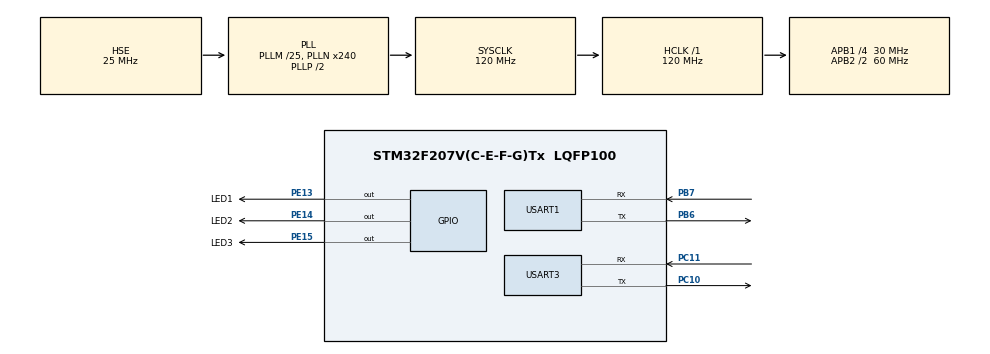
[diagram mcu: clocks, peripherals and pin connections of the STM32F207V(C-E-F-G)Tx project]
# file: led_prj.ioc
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Mcu.Family=STM32F2
Mcu.Name=STM32F207V(C-E-F-G)Tx
Mcu.Package=LQFP100
NVIC.PriorityGroup=NVIC_PRIORITYGROUP_4
PB6.Mode=Asynchronous
PB6.Signal=USART1_TX
PB7.Mode=Asynchronous
PB7.Signal=USART1_RX
PC10.Mode=Asynchronous
PC10.Signal=USART3_TX
PC11.Mode=Asynchronous
PC11.Signal=USART3_RX
PE13.GPIO_Label=LED1
PE13.PinState=GPIO_PIN_SET
PE13.Signal=GPIO_Output
PE14.GPIO_Label=LED2
PE14.PinState=GPIO_PIN_SET
PE14.Signal=GPIO_Output
PE15.GPIO_Label=LED3
PE15.PinState=GPIO_PIN_SET
PE15.Signal=GPIO_Output
PH0-OSC_IN.Mode=HSE-External-Oscillator
PH0-OSC_IN.Signal=RCC_OSC_IN
PH1-OSC_OUT.Mode=HSE-External-Oscillator
PH1-OSC_OUT.Signal=RCC_OSC_OUT
ProjectManager.HeapSize=0x200
ProjectManager.StackSize=0x400
ProjectManager.TargetToolchain=STM32CubeIDE
RCC.48MHZClocksFreq_Value=60000000
RCC.AHBFreq_Value=120000000
RCC.APB1CLKDivider=RCC_HCLK_DIV4
RCC.APB1Freq_Value=30000000
RCC.APB1TimFreq_Value=60000000
RCC.APB2CLKDivider=RCC_HCLK_DIV2
RCC.APB2Freq_Value=60000000
RCC.APB2TimFreq_Value=120000000
RCC.CortexFreq_Value=120000000
RCC.HCLKFreq_Value=120000000
RCC.HSE_VALUE=25000000
RCC.HSI_VALUE=16000000
RCC.LSE_VALUE=32768
RCC.PLLM=25
RCC.PLLN=240
RCC.PLLSourceVirtual=RCC_PLLSOURCE_HSE
RCC.SYSCLKFreq_VALUE=120000000
RCC.SYSCLKSource=RCC_SYSCLKSOURCE_PLLCLK
RCC.VCOOutputFreq_Value=240000000
USART1.VirtualMode=VM_ASYNC
USART3.VirtualMode=VM_ASYNC
board=custom

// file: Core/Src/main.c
/* USER CODE BEGIN Header */
/**
  ******************************************************************************
  * @file           : main.c
  * @brief          : Main program body
  ******************************************************************************
  * @attention
  *
  * Copyright (c) 2023 STMicroelectronics.
  * All rights reserved.
  *
  * This software is licensed under terms that can be found in the LICENSE file
  * in the root directory of this software component.
  * If no LICENSE file comes with this software, it is provided AS-IS.
  *
  ******************************************************************************
  */
/* USER CODE END Header */
#include "main.h"

/* USER CODE BEGIN Includes */
#include <stdio.h>
/* USER CODE END Includes */

UART_HandleTypeDef huart1;
UART_HandleTypeDef huart3;

void SystemClock_Config(void);
static void MX_GPIO_Init(void);
static void MX_USART1_UART_Init(void);
static void MX_USART3_UART_Init(void);

/* USER CODE BEGIN 0 */
#define hUART           huart3
int _write( int32_t file , uint8_t *ptr , int32_t len )
{
    /* Implement your write code here, this is used by puts and printf for example */
    for ( int16_t i = 0 ; i < len ; ++i )
    {
        HAL_UART_Transmit( &hUART, ptr++, 1, 100);
    }
    return len;
}
/* USER CODE END 0 */

int main(void)
{

  /* MCU Configuration--------------------------------------------------------*/

  /* Reset of all peripherals, Initializes the Flash interface and the Systick. */
  HAL_Init();

  /* Configure the system clock */
  SystemClock_Config();

  /* Initialize all configured peripherals */
  MX_GPIO_Init();
  MX_USART1_UART_Init();
  MX_USART3_UART_Init();
  /* USER CODE BEGIN 2 */
  int count = 0;
  printf("LED test\r\n");
  /* USER CODE END 2 */

  /* Infinite loop */
  /* USER CODE BEGIN WHILE */
  while (1)
  {
	HAL_GPIO_WritePin(LED1_GPIO_Port, LED1_Pin, !(count & 0x01));
	HAL_GPIO_WritePin(LED2_GPIO_Port, LED2_Pin, !((count >> 1) & 0x01));
	HAL_GPIO_WritePin(LED3_GPIO_Port, LED3_Pin, !((count >> 2) & 0x01));
	count = (count + 1) % 8;
	HAL_Delay(1000);
    /* USER CODE END WHILE */

  }
}

void SystemClock_Config(void)
{
  RCC_OscInitTypeDef RCC_OscInitStruct = {0};
  RCC_ClkInitTypeDef RCC_ClkInitStruct = {0};

  /** Initializes the RCC Oscillators according to the specified parameters
  * in the RCC_OscInitTypeDef structure.
  */
  RCC_OscInitStruct.OscillatorType = RCC_OSCILLATORTYPE_HSE;
  RCC_OscInitStruct.HSEState = RCC_HSE_ON;
  RCC_OscInitStruct.PLL.PLLState = RCC_PLL_ON;
  RCC_OscInitStruct.PLL.PLLSource = RCC_PLLSOURCE_HSE;
  RCC_OscInitStruct.PLL.PLLM = 25;
  RCC_OscInitStruct.PLL.PLLN = 240;
  RCC_OscInitStruct.PLL.PLLP = RCC_PLLP_DIV2;
  RCC_OscInitStruct.PLL.PLLQ = 4;
  if (HAL_RCC_OscConfig(&RCC_OscInitStruct) != HAL_OK)
  {
    Error_Handler();
  }

  /** Initializes the CPU, AHB and APB buses clocks
  */
  RCC_ClkInitStruct.ClockType = RCC_CLOCKTYPE_HCLK|RCC_CLOCKTYPE_SYSCLK
                              |RCC_CLOCKTYPE_PCLK1|RCC_CLOCKTYPE_PCLK2;
  RCC_ClkInitStruct.SYSCLKSource = RCC_SYSCLKSOURCE_PLLCLK;
  RCC_ClkInitStruct.AHBCLKDivider = RCC_SYSCLK_DIV1;
  RCC_ClkInitStruct.APB1CLKDivider = RCC_HCLK_DIV4;
  RCC_ClkInitStruct.APB2CLKDivider = RCC_HCLK_DIV2;

  if (HAL_RCC_ClockConfig(&RCC_ClkInitStruct, FLASH_LATENCY_3) != HAL_OK)
  {
    Error_Handler();
  }
}

static void MX_USART1_UART_Init(void)
{

  huart1.Instance = USART1;
  huart1.Init.BaudRate = 115200;
  huart1.Init.WordLength = UART_WORDLENGTH_8B;
  huart1.Init.StopBits = UART_STOPBITS_1;
  huart1.Init.Parity = UART_PARITY_NONE;
  huart1.Init.Mode = UART_MODE_TX_RX;
  huart1.Init.HwFlowCtl = UART_HWCONTROL_NONE;
  huart1.Init.OverSampling = UART_OVERSAMPLING_16;
  if (HAL_UART_Init(&huart1) != HAL_OK)
  {
    Error_Handler();
  }

}

static void MX_USART3_UART_Init(void)
{

  huart3.Instance = USART3;
  huart3.Init.BaudRate = 115200;
  huart3.Init.WordLength = UART_WORDLENGTH_8B;
  huart3.Init.StopBits = UART_STOPBITS_1;
  huart3.Init.Parity = UART_PARITY_NONE;
  huart3.Init.Mode = UART_MODE_TX_RX;
  huart3.Init.HwFlowCtl = UART_HWCONTROL_NONE;
  huart3.Init.OverSampling = UART_OVERSAMPLING_16;
  if (HAL_UART_Init(&huart3) != HAL_OK)
  {
    Error_Handler();
  }

}

static void MX_GPIO_Init(void)
{
  GPIO_InitTypeDef GPIO_InitStruct = {0};

  /* GPIO Ports Clock Enable */
  __HAL_RCC_GPIOH_CLK_ENABLE();
  __HAL_RCC_GPIOE_CLK_ENABLE();
  __HAL_RCC_GPIOC_CLK_ENABLE();
  __HAL_RCC_GPIOB_CLK_ENABLE();

  /*Configure GPIO pin Output Level */
  HAL_GPIO_WritePin(GPIOE, LED1_Pin|LED2_Pin|LED3_Pin, GPIO_PIN_SET);

  /*Configure GPIO pins : LED1_Pin LED2_Pin LED3_Pin */
  GPIO_InitStruct.Pin = LED1_Pin|LED2_Pin|LED3_Pin;
  GPIO_InitStruct.Mode = GPIO_MODE_OUTPUT_PP;
  GPIO_InitStruct.Pull = GPIO_NOPULL;
  GPIO_InitStruct.Speed = GPIO_SPEED_FREQ_LOW;
  HAL_GPIO_Init(GPIOE, &GPIO_InitStruct);

}

void Error_Handler(void)
{
  __disable_irq();
  while (1)
  {
  }
}
